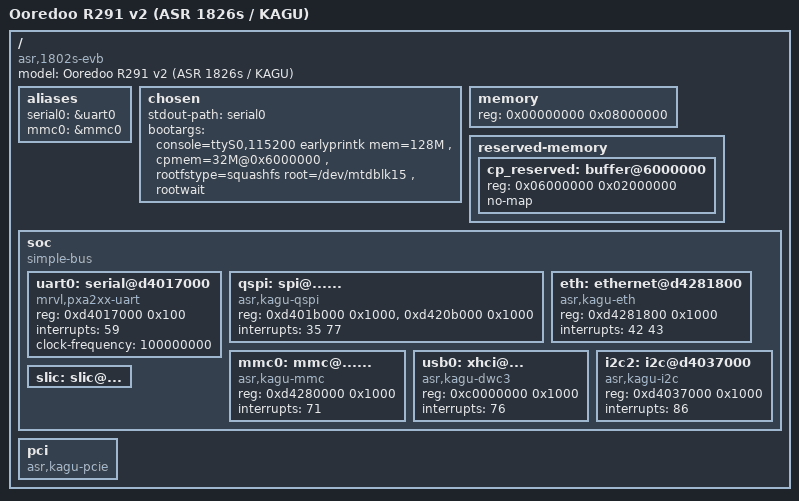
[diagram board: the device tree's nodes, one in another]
// SPDX-License-Identifier: GPL-2.0
/*
 * Skeleton Device Tree for Ooredoo R291 v2 (ASR 1826s / KAGU).
 *
 * SoC : ASR1802S (ARMv7-Cortex-A9), 128 MiB RAM, 32 MiB CP carve-out.
 * All MMIO / IRQ / partition values were read at runtime from a shipping
 * unit (kernel 3.10.33 vendor): /proc/iomem, /proc/interrupts, /proc/mtd
 * and U-Boot env (mtd21 bootargs).  Peripheral driver compatible strings
 * are RFC placeholders pending the ASR1802S SoC port to mainline.
 */

/dts-v1/;
#include "asr1802s.dtsi"   /* <-- to be added: clock/reset/pinctrl DDR/ICU */

/ {
        model = "Ooredoo R291 v2 (ASR 1826s / KAGU)";
        compatible = "asr,1802s-evb", "asr,1802s";

        aliases {
                serial0 = &uart0;
                mmc0    = &mmc0;
        };

        chosen {
                stdout-path = "serial0";
                bootargs = "console=ttyS0,115200 earlyprintk mem=128M "
                              "cpmem=32M@0x6000000 "
                              "rootfstype=squashfs root=/dev/mtdblk15 "
                              "rootwait";
        };

        memory {
                device_type = "memory";
                /* 0x00000000 - 0x07ffffff : 128 MiB */
                reg = <0x00000000 0x08000000>;
        };

        reserved-memory {
                #address-cells = <1>;
                #size-cells = <1>;
                ranges;
                /* cpmem=32M@0x06000000 reserved for the Communication Processor */
                cp_reserved: buffer@6000000 {
                        reg = <0x06000000 0x02000000>;
                        no-map;
                };
        };

        soc {
                compatible = "simple-bus";
                #address-cells = <1>;
                #size-cells = <1>;
                ranges = <0xd4000000 0xd4000000 0x2000000>,  /* APB */
                         <0xd4200000 0xd4200000 0x1000000>,  /* AXI periphs */
                         <0xd8000000 0xd8000000 0x0400000>,  /* PCIe wlan0 MMIO */
                         <0xe0000000 0xe0000000 0x0400000>;  /* PCIe wlan1 MMIO */

                /* UART0 / serial console */
                uart0: serial@d4017000 {
                        compatible = "mrvl,pxa2xx-uart";
                        reg = <0xd4017000 0x100>;
                        interrupts = <59>;
                        clock-frequency = <100000000>;
                        status = "okay";
                };

                /* QSPI -> SPI-NAND F35UQA001G (25 MTD banks in /proc/mtd) */
                qspi: spi@...... {
                        compatible = "asr,kagu-qspi";
                        reg = <0xd401b000 0x1000>,
                              <0xd420b000 0x1000>;        /* qspi + qspi-ctrl */
                        interrupts = <35 77>;              /* asr-spi.0 ، qspi */
                        #address-cells = <1>;
                        #size-cells = <0>;
                        /*
                         * Partition map (from /proc/mtd — keep in sync):
                         *   00 bootloader        0x040000
                         *   01 cp_reliabledata  0x020000  (U-Boot env + CP NVM)
                         *   05/06 mep-ota (+bk)
                         *   07/08 dtim-a/dtim-b 0x040000
                         *   09/10 cpimage-a/b   0x00f00000
                         *   11/12 u-boot-a/b    0x0c0000
                         *   13/14 kernel-a/b    0x0500000
                         *   15/16 rootfs-a/b    0x01400000  <- /dev/root = rootfs-a
                         *   17/18 oem_data-a/b  0x00600000
                         *   21 bootargs         0x00040000
                         *   23 rootfs_data      0x018c0000  (UBI volume)
                         */
                };

                /* ASR Ethernet MAC + YT9215 switch */
                eth: ethernet@d4281800 {
                        compatible = "asr,kagu-eth";
                        reg = <0xd4281800 0x1000>;
                        interrupts = <42 43>;   /* eth0 RX/TX */
                        /* DSA/YT9215 on the MDIO bus (br-lan) */
                        #address-cells = <1>;
                        #size-cells = <0>;
                        status = "okay";
                };

                /* MMC0 */
                mmc0: mmc@...... {
                        compatible = "asr,kagu-mmc";
                        reg = <0xd4280000 0x1000>;
                        interrupts = <71>;
                        status = "okay";
                };

                /* USB3 DW3 */
                usb0: xhci@... {
                        compatible = "asr,kagu-dwc3";
                        reg = <0xc0000000 0x1000>;
                        interrupts = <76>;
                };

                /* I2C.2 -> PMIC 88PM802 @0x30 */
                i2c2: i2c@d4037000 {
                        compatible = "asr,kagu-i2c";
                        reg = <0xd4037000 0x1000>;
                        interrupts = <86>;
                        /* #address-cells=<1>; #size-cells=<0>; */
                        /* pmic: 88pm80x@30 { compatible = "marvell,88pm802"; }; */
                };

                /* SLIC VoIP (MAX1919) — GPIO23 reset, GPIO24 wakeup */
                slic: slic@... { /* maxlinear,max1919 */ };
        };

        /* Two PCIe Gen1x1 endpoints -> RTL8812FE wlan0/wlan1 */
        pci {
                compatible = "asr,kagu-pcie";
                #address-cells = <3>;
                #interrupt-cells = <1>;
                /* wlan0 @ 0xd8200000 irq 26 ; wlan1 @ 0xe0100000 irq 250 */
        };

        /* MAC addresses / identity come from the per-unit TTPCom NVM
         * under /overlay/root/NVM/ — preserve across any reflash. */
};
